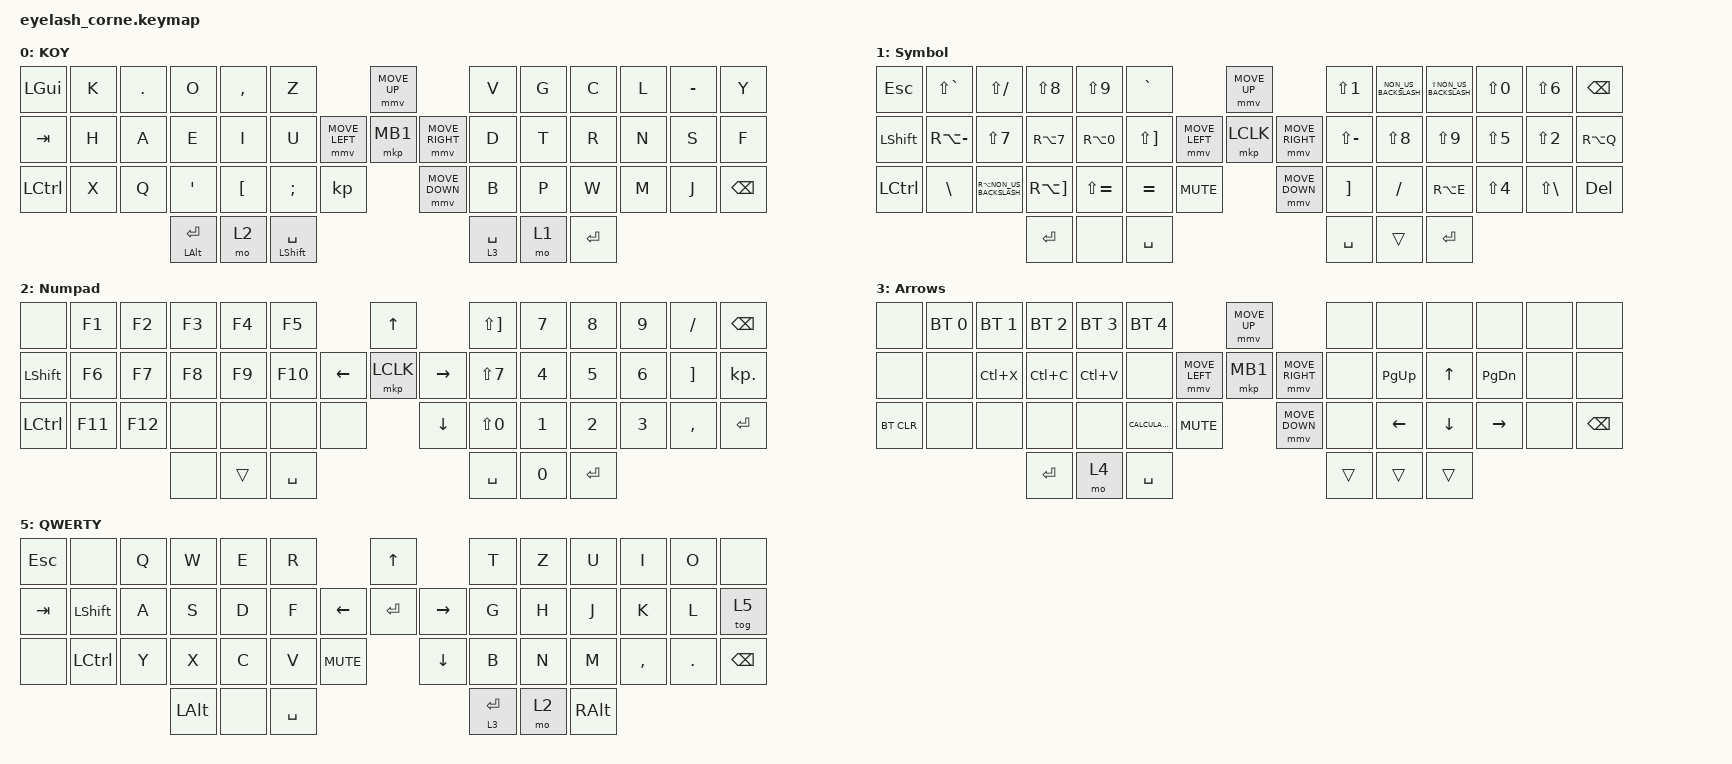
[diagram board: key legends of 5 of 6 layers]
#include <dt-bindings/zmk/mouse.h>
#include <input/processors.dtsi>
#include <behaviors.dtsi>
#include <dt-bindings/zmk/backlight.h>
#include <dt-bindings/zmk/bt.h>
#include <dt-bindings/zmk/keys.h>
#include <dt-bindings/zmk/pointing.h>
#include <dt-bindings/zmk/pointing.h>
#include <dt-bindings/zmk/pointing.h>
#include <dt-bindings/zmk/rgb.h>

/*

   &mmv_input_listener {
       input-processors = <&zip_xy_scaler 2 1>;
   };

   &msc_input_listener {
       input-processors = <&zip_xy_scaler 2 1>;
   };

 */

#define ZMK_MOUSE_DEFAULT_MOVE_VAL 1200  // 600
#define ZMK_MOUSE_DEFAULT_SCRL_VAL 20    // 10

&mt { tapping-term-ms = <150>; };

&mmv { acceleration-exponent = <0>; };

/ {
    behaviors {
        td0: td0 {
            compatible = "zmk,behavior-tap-dance";
            display-name = "Shift/Caps Lock Tap Dance";
            #binding-cells = <0>;
            bindings = <&kp LEFT_SHIFT>, <&kp CAPS>;
        };

        Zoom_Rotator: Zoom_Rotator {
            compatible = "zmk,behavior-sensor-rotate";
            label = "ZOOM_ROTATOR";
            #sensor-binding-cells = <0>;
            bindings = <&Zoom_In>, <&Zoom_out>;

            tap-ms = <30>;
        };

        scroll_encoder_horizontal: scroll_encoder_horizontal {
            compatible = "zmk,behavior-sensor-rotate";
            label = "SCROLL_ENCODER_HORIZONTAL";
            #sensor-binding-cells = <0>;
            bindings = <&msc SCRL_LEFT>, <&msc SCRL_RIGHT>;

            tap-ms = <30>;
        };
    };

    rgb_encoder: rgb_encoder {
        compatible = "zmk,behavior-sensor-rotate";
        #sensor-binding-cells = <0>;
        bindings = <&rgb_ug RGB_BRI>, <&rgb_ug RGB_BRD>;
    };

    scroll_encoder: scroll_encoder {
        compatible = "zmk,behavior-sensor-rotate";
        #sensor-binding-cells = <0>;
        bindings = <&msc SCRL_DOWN>, <&msc SCRL_UP>;

        tap-ms = <30>;
    };

    macros {
        Zoom_In: Zoom_In {
            compatible = "zmk,behavior-macro";
            #binding-cells = <0>;
            bindings = <&kp LEFT_CONTROL &msc SCRL_UP>;
            label = "ZOOM_IN";
        };

        Zoom_out: Zoom_out {
            compatible = "zmk,behavior-macro";
            #binding-cells = <0>;
            bindings = <&kp LEFT_CONTROL &msc SCRL_DOWN>;
            label = "ZOOM_OUT";
        };
    };

    keymap {
        compatible = "zmk,keymap";

        KOY {
            bindings = <
&kp LGUI   &kp K  &kp DOT  &kp O               &kp COMMA         &kp Z                                        &mmv MOVE_UP                     &kp V        &kp G  &kp C      &kp L  &kp MINUS  &kp Y
&kp TAB    &kp H  &kp A    &kp E               &kp I             &kp U                        &mmv MOVE_LEFT  &mkp MB1        &mmv MOVE_RIGHT  &kp D        &kp T  &kp R      &kp N  &kp S      &kp F
&kp LCTRL  &kp X  &kp Q    &kp SINGLE_QUOTE    &kp LEFT_BRACKET  &kp SEMI              &kp                    &mmv MOVE_DOWN                   &kp B        &kp P  &kp W      &kp M  &kp J      &kp BSPC
                           &mt LEFT_ALT ENTER  &mo 2             &mt LEFT_SHIFT SPACE                                                          &lt 3 SPACE  &mo 1  &kp ENTER
            >;

            sensor-bindings = <&scroll_encoder>;
        };

        Symbol {
            display-name = "Symbol";
            bindings = <
&kp ESCAPE        &kp LS(GRAVE)  &kp LS(SLASH)             &kp LS(N8)             &kp LS(N9)     &kp GRAVE                                            &mmv MOVE_UP                     &kp LS(NUMBER_1)   &kp NON_US_BACKSLASH  &kp LS(NON_US_BACKSLASH)  &kp LS(N0)        &kp LS(NUMBER_6)   &kp BSPC
&kp LEFT_SHIFT    &kp RA(MINUS)  &kp LS(N7)                &kp RA(N7)             &kp RA(N0)     &kp LS(RIGHT_BRACKET)                &mmv MOVE_LEFT  &mkp LCLK       &mmv MOVE_RIGHT  &kp LS(MINUS)      &kp LS(N8)            &kp LS(N9)                &kp LS(N5)        &kp LS(NUMBER_2)   &kp RA(Q)
&kp LEFT_CONTROL  &kp BACKSLASH  &kp RA(NON_US_BACKSLASH)  &kp RA(RIGHT_BRACKET)  &kp LS(EQUAL)  &kp EQUAL              &kp C_MUTE                    &mmv MOVE_DOWN                   &kp RIGHT_BRACKET  &kp SLASH             &kp RA(E)                 &kp LS(NUMBER_4)  &kp LS(BACKSLASH)  &kp DELETE
                                                           &kp ENTER              &none          &kp SPACE                                                                             &kp SPACE          &trans                &kp ENTER
            >;

            sensor-bindings = <&scroll_encoder_horizontal>;
        };

        Numpad {
            display-name = "Numpad";
            bindings = <
&none             &kp F1   &kp F2   &kp F3  &kp F4  &kp F5                        &kp UP_ARROW             &kp LS(RIGHT_BRACKET)  &kp N7        &kp N8        &kp N9        &kp SLASH          &kp BSPC
&kp LEFT_SHIFT    &kp F6   &kp F7   &kp F8  &kp F9  &kp F10             &kp LEFT  &mkp LCLK     &kp RIGHT  &kp LS(N7)             &kp NUMBER_4  &kp N5        &kp NUMBER_6  &kp RIGHT_BRACKET  &kp KP_DOT
&kp LEFT_CONTROL  &kp F11  &kp F12  &none   &none   &none      &none              &kp DOWN                 &kp LS(N0)             &kp NUMBER_1  &kp NUMBER_2  &kp NUMBER_3  &kp COMMA          &kp ENTER
                                    &none   &trans  &kp SPACE                                              &kp SPACE              &kp N0        &kp ENTER
            >;

            sensor-bindings = <&Zoom_Rotator>;
        };

        Arrows {
            display-name = "Arrows";
            bindings = <
&none       &bt BT_SEL 0  &bt BT_SEL 1  &bt BT_SEL 2  &bt BT_SEL 3  &bt BT_SEL 4                                    &mmv MOVE_UP                     &none   &none        &none         &none          &none  &none
&none       &none         &kp LC(X)     &kp LC(C)     &kp LC(V)     &none                           &mmv MOVE_LEFT  &mkp MB1        &mmv MOVE_RIGHT  &none   &kp PAGE_UP  &kp UP_ARROW  &kp PAGE_DOWN  &none  &none
&bt BT_CLR  &none         &none         &none         &none         &kp K_CALCULATOR  &kp C_MUTE                    &mmv MOVE_DOWN                   &none   &kp LEFT     &kp DOWN      &kp RIGHT      &none  &kp BACKSPACE
                                        &kp ENTER     &mo 4         &kp SPACE                                                                        &trans  &trans       &trans
            >;

            sensor-bindings = <&Zoom_Rotator>;
        };

        Settings {
            bindings = <
&rgb_ug RGB_BRI  &rgb_ug RGB_SAI  &rgb_ug RGB_HUI  &rgb_ug RGB_SPI                   &none                             &none                  &none          &none           &none           &none           &none            &none  &bl BL_INC
&rgb_ug RGB_BRD  &rgb_ug RGB_SAD  &rgb_ug RGB_HUD  &rgb_ug RGB_SPD                   &none                             &none           &none  &tog 5  &none  &msc SCRL_UP    &mkp MB1        &mmv MOVE_UP    &mkp MB2         &none  &bl BL_DEC
&rgb_ug RGB_TOG  &rgb_ug RGB_EFR  &rgb_ug RGB_EFF  &rgb_ug RGB_COLOR_HSB(28,100,50)  &rgb_ug RGB_COLOR_HSB(303,65,40)  &none  &none           &none          &msc SCRL_DOWN  &mmv MOVE_LEFT  &mmv MOVE_DOWN  &mmv MOVE_RIGHT  &none  &bl BL_TOG
                                                   &none                             &trans                            &none                                 &none           &none           &none
            >;
        };

        QWERTY {
            display-name = "QWERTY";
            bindings = <
&kp ESCAPE  &none             &kp Q  &kp W         &kp E  &kp R                              &kp UP                &kp T        &kp Z  &kp U     &kp I      &kp O    &none
&kp TAB     &kp LEFT_SHIFT    &kp A  &kp S         &kp D  &kp F                    &kp LEFT  &kp ENTER  &kp RIGHT  &kp G        &kp H  &kp J     &kp K      &kp L    &tog 5
&none       &kp LEFT_CONTROL  &kp Y  &kp X         &kp C  &kp V      &kp K_MUTE              &kp DOWN              &kp B        &kp N  &kp M     &kp COMMA  &kp DOT  &kp BACKSPACE
                                     &kp LEFT_ALT  &none  &kp SPACE                                                &lt 3 ENTER  &mo 2  &kp RALT
            >;

            sensor-bindings = <&inc_dec_kp C_VOLUME_UP C_VOLUME_DOWN>;
        };
    };
};

